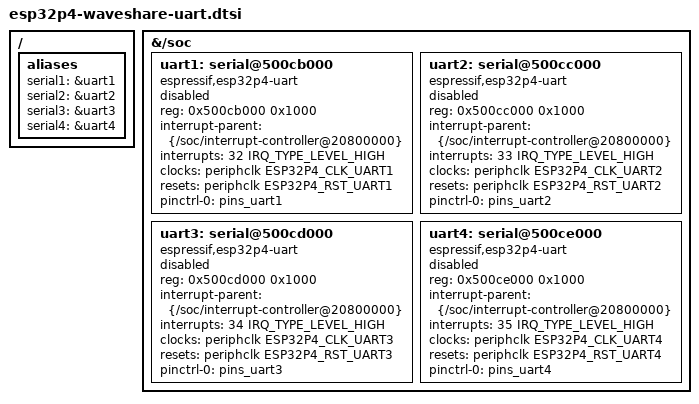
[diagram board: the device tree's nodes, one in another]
// SPDX-License-Identifier: (GPL-2.0-only OR BSD-2-Clause)
#include <dt-bindings/interrupt-controller/irq.h>

/ {
	aliases {
		serial1 = &uart1;
		serial2 = &uart2;
		serial3 = &uart3;
		serial4 = &uart4;
	};
};

&{/soc} {
	/* TRM ch.46 UART Controller and ch.14 Interrupt Matrix. */
	uart1: serial@500cb000 {
		compatible = "espressif,esp32p4-uart";
		reg = <0x500cb000 0x1000>;
		interrupt-parent = <&{/soc/interrupt-controller@20800000}>;
		interrupts = <32 IRQ_TYPE_LEVEL_HIGH>;
		clocks = <&periphclk ESP32P4_CLK_UART1>;
		resets = <&periphclk ESP32P4_RST_UART1>;
		pinctrl-names = "default";
		pinctrl-0 = <&pins_uart1>;
		status = "disabled";
	};

	uart2: serial@500cc000 {
		compatible = "espressif,esp32p4-uart";
		reg = <0x500cc000 0x1000>;
		interrupt-parent = <&{/soc/interrupt-controller@20800000}>;
		interrupts = <33 IRQ_TYPE_LEVEL_HIGH>;
		clocks = <&periphclk ESP32P4_CLK_UART2>;
		resets = <&periphclk ESP32P4_RST_UART2>;
		pinctrl-names = "default";
		pinctrl-0 = <&pins_uart2>;
		status = "disabled";
	};

	uart3: serial@500cd000 {
		compatible = "espressif,esp32p4-uart";
		reg = <0x500cd000 0x1000>;
		interrupt-parent = <&{/soc/interrupt-controller@20800000}>;
		interrupts = <34 IRQ_TYPE_LEVEL_HIGH>;
		clocks = <&periphclk ESP32P4_CLK_UART3>;
		resets = <&periphclk ESP32P4_RST_UART3>;
		pinctrl-names = "default";
		pinctrl-0 = <&pins_uart3>;
		status = "disabled";
	};

	uart4: serial@500ce000 {
		compatible = "espressif,esp32p4-uart";
		reg = <0x500ce000 0x1000>;
		interrupt-parent = <&{/soc/interrupt-controller@20800000}>;
		interrupts = <35 IRQ_TYPE_LEVEL_HIGH>;
		clocks = <&periphclk ESP32P4_CLK_UART4>;
		resets = <&periphclk ESP32P4_RST_UART4>;
		pinctrl-names = "default";
		pinctrl-0 = <&pins_uart4>;
		status = "disabled";
	};
};
